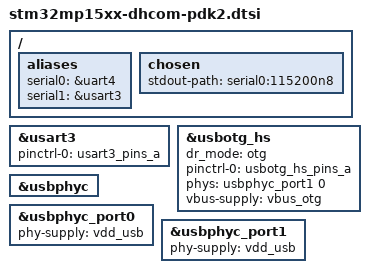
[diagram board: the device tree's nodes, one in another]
// SPDX-License-Identifier: GPL-2.0-or-later OR BSD-3-Clause
/*
 * Copyright (C) 2019-2020 Marek Vasut <marex@denx.de>
 * Copyright (C) 2022 DH electronics GmbH
 */

/ {
	aliases {
		serial0 = &uart4;
		serial1 = &usart3;
	};

	chosen {
		stdout-path = "serial0:115200n8";
	};
};

&usart3 {
	pinctrl-names = "default";
	pinctrl-0 = <&usart3_pins_a>;
	status = "okay";
};

&usbotg_hs {
	dr_mode = "otg";
	pinctrl-0 = <&usbotg_hs_pins_a>;
	pinctrl-names = "default";
	phy-names = "usb2-phy";
	phys = <&usbphyc_port1 0>;
	vbus-supply = <&vbus_otg>;
	status = "okay";
};

&usbphyc {
	status = "okay";
};

&usbphyc_port0 {
	phy-supply = <&vdd_usb>;
};

&usbphyc_port1 {
	phy-supply = <&vdd_usb>;
};
